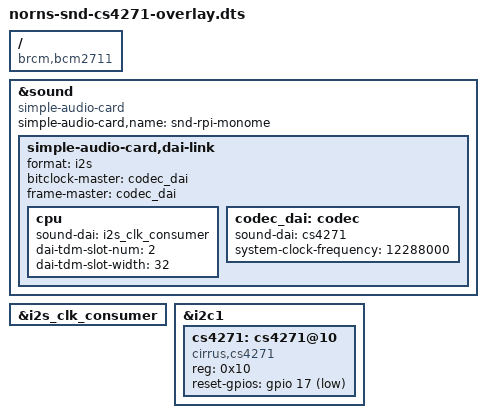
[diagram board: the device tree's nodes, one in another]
// SPDX-License-Identifier: GPL-2.0
/*
 * norns shield sound card, Cirrus Logic CS4271 codec, for the Raspberry Pi 4.
 *
 * Derived from monome/linux branch norns-5.10.y,
 * arch/arm/boot/dts/overlays/monome-snd-4271-overlay.dts (GPL-2.0).
 * Changes from monome's overlay:
 *  - compatible: brcm,bcm2711 (Pi 4) instead of brcm,bcm2708.
 *  - The I2S controller is referenced as &i2s_clk_consumer, the label the
 *    Raspberry Pi base device trees give the controller that takes its bit
 *    and frame clocks from the codec (on the Pi 4 the same node as &i2s).
 *  - The codec reset is reset-gpios (the binding's name; the kernel also
 *    reads monome's reset-gpio) on GPIO17, GPIO_ACTIVE_LOW (1): since its
 *    conversion to GPIO descriptors cs4271.c treats logical 1 as "held in
 *    reset" (cs4271_reset() sets 1, then 0). With monome's flags (2, active
 *    high) the 6.x driver would leave the codec in reset; the 5.10 driver
 *    drove the raw line and ignored the flags.
 *  - monome's reset_pin gpio-hog child is gone: a hog only works under a
 *    gpio-controller node, so the kernel never applied it, and the codec
 *    driver owns GPIO17.
 */
/dts-v1/;
/plugin/;

/ {
	compatible = "brcm,bcm2711";

	fragment@0 {
		target = <&sound>;
		__overlay__ {
			compatible = "simple-audio-card";
			status = "okay";
			simple-audio-card,name = "snd-rpi-monome";
			simple-audio-card,dai-link {
				format = "i2s";
				bitclock-master = <&codec_dai>;
				frame-master = <&codec_dai>;
				cpu {
					sound-dai = <&i2s_clk_consumer>;
					dai-tdm-slot-num = <2>;
					dai-tdm-slot-width = <32>;
				};
				codec_dai: codec {
					sound-dai = <&cs4271>;
					system-clock-frequency = <12288000>;
				};
			};
		};
	};

	fragment@1 {
		target = <&i2s_clk_consumer>;
		__overlay__ {
			status = "okay";
		};
	};

	fragment@2 {
		target = <&i2c1>;
		__overlay__ {
			#address-cells = <1>;
			#size-cells = <0>;
			status = "okay";

			cs4271: cs4271@10 {
				#sound-dai-cells = <0>;
				compatible = "cirrus,cs4271";
				reg = <0x10>;
				reset-gpios = <&gpio 17 1>;
				status = "okay";
			};
		};
	};
};
